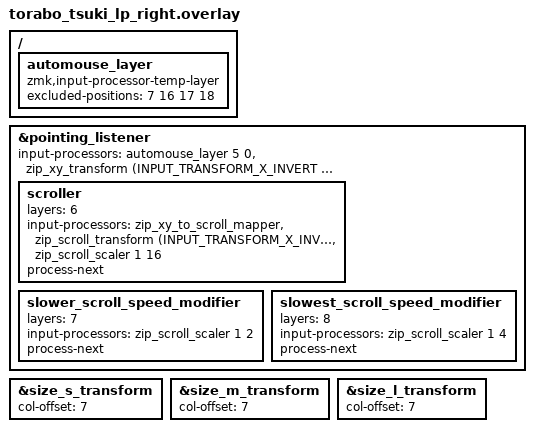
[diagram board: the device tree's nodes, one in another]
#include "torabo_tsuki_lp.dtsi"
#include <input/processors.dtsi>
#include <dt-bindings/zmk/input_transform.h>

/ {
    /*
     * Enable the automouse layer on trackball movement without a timeout.
     * Keep the layer active for I/J/K/L so their mouse bindings are used.
     * Any other key press dismisses the temporary mouse layer.
     */
    automouse_layer: automouse_layer {
        compatible = "zmk,input-processor-temp-layer";
        #input-processor-cells = <2>;
        excluded-positions = <7 16 17 18>;
    };
};

&pointing_listener {
    input-processors = <&automouse_layer 5 0>,
                       <&zip_xy_transform (INPUT_TRANSFORM_X_INVERT | INPUT_TRANSFORM_Y_INVERT)>;

    /* K enables scrolling. The default speed is the previous slow setting. */
    scroller {
        layers = <6>;
        input-processors = <&zip_xy_to_scroll_mapper>,
                           <&zip_scroll_transform (INPUT_TRANSFORM_X_INVERT | INPUT_TRANSFORM_Y_INVERT)>,
                           <&zip_scroll_scaler 1 16>;
        process-next;
    };

    /* The speed-cycle key selects these relative modifiers. */
    slower_scroll_speed_modifier {
        layers = <7>;
        input-processors = <&zip_scroll_scaler 1 2>;
        process-next;
    };

    slowest_scroll_speed_modifier {
        layers = <8>;
        input-processors = <&zip_scroll_scaler 1 4>;
        process-next;
    };
};

&size_s_transform {
    col-offset = <7>;
};

&size_m_transform {
    col-offset = <7>;
};

&size_l_transform {
    col-offset = <7>;
};
